CM_ "Nissan Leaf receive-side DBC for Cabana. Includes locally defined steering, blinkers, hazards, doors, pedals, wheel speed, gearbox, and related signals.";

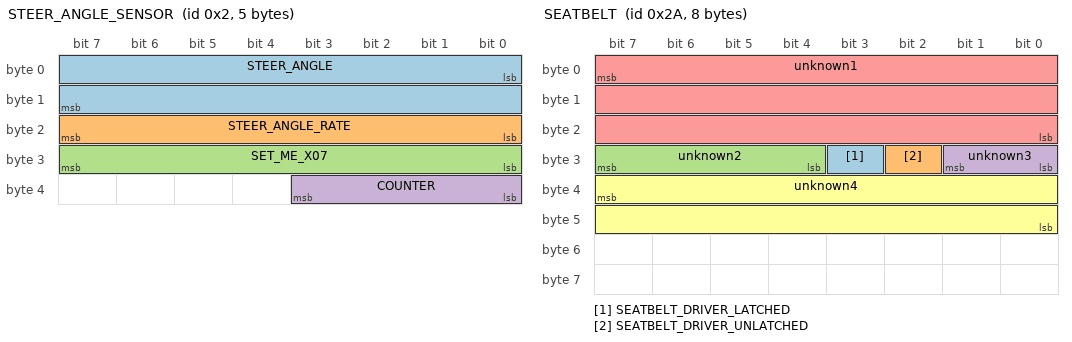
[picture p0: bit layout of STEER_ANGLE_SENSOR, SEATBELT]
BO_ 2 STEER_ANGLE_SENSOR: 5 XXX
 SG_ STEER_ANGLE : 0|16@1- (-0.1,0) [-3276.7|3276.8] "deg" XXX
 SG_ STEER_ANGLE_RATE : 16|8@1+ (1,0) [0|255] "" XXX
 SG_ SET_ME_X07 : 24|8@1+ (1,0) [0|255] "" XXX
 SG_ COUNTER : 32|4@1+ (1,0) [0|15] "" XXX

BO_ 42 SEATBELT: 8 XXX
 SG_ SEATBELT_DRIVER_LATCHED : 27|1@1+ (1,0) [0|3] "" XXX
 SG_ SEATBELT_DRIVER_UNLATCHED : 26|1@0+ (1,0) [0|1] "" XXX
 SG_ unknown2 : 31|4@0+ (1,0) [0|15] "" XXX
 SG_ unknown3 : 24|2@1+ (1,0) [0|3] "" XXX
 SG_ unknown1 : 7|24@0+ (1,0) [0|16777215] "" XXX
 SG_ unknown4 : 39|16@0+ (1,0) [0|65535] "" XXX

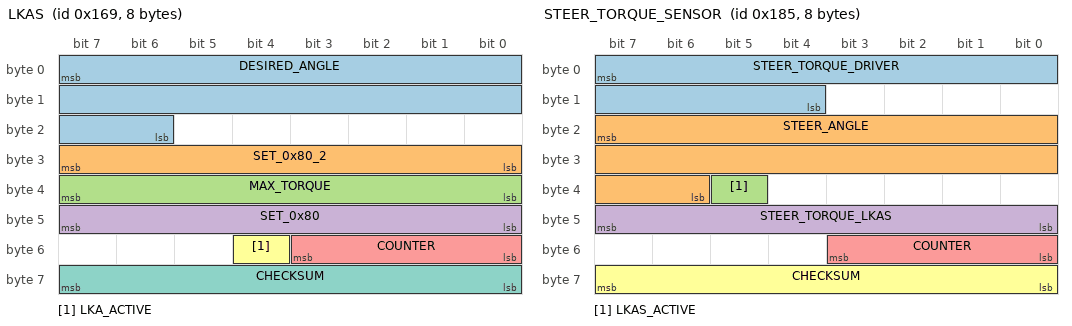
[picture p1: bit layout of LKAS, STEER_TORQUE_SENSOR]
BO_ 361 LKAS: 8 XXX
 SG_ DESIRED_ANGLE : 7|18@0+ (-0.01,1310) [-1311.43|1310] "deg" XXX
 SG_ SET_0x80_2 : 31|8@0+ (1,0) [0|255] "" XXX
 SG_ MAX_TORQUE : 39|8@0+ (0.01,0) [0|2.55] "Nm" XXX
 SG_ SET_0x80 : 47|8@0+ (1,0) [0|255] "" XXX
 SG_ COUNTER : 51|4@0+ (1,0) [0|15] "" XXX
 SG_ LKA_ACTIVE : 52|1@0+ (1,0) [0|1] "" XXX
 SG_ CHECKSUM : 63|8@0+ (1,0) [0|255] "" XXX

BO_ 389 STEER_TORQUE_SENSOR: 8 XXX
 SG_ STEER_TORQUE_DRIVER : 7|12@0+ (-0.01,20.47) [-20.48|20.47] "Nm" XXX
 SG_ STEER_ANGLE : 23|18@0+ (-0.01,1310) [-1311.43|1310] "deg" XXX
 SG_ LKAS_ACTIVE : 37|1@0+ (1,0) [0|1] "" XXX
 SG_ STEER_TORQUE_LKAS : 47|8@0+ (1,0) [0|255] "" XXX
 SG_ COUNTER : 51|4@0+ (1,0) [0|15] "" XXX
 SG_ CHECKSUM : 63|8@0+ (1,0) [0|255] "" XXX

BO_ 460 BRAKE_PEDAL: 8 XXX
 SG_ BRAKE_PEDAL : 7|8@0+ (1,0) [0|256] "" XXX

BO_ 569 CRUISE_THROTTLE: 8 XXX
 SG_ GAS_PEDAL_INVERTED : 15|8@0+ (1,0) [0|255] "" XXX
 SG_ GAS_PEDAL : 7|8@0+ (1,0) [0|255] "" XXX
 SG_ CRUISE_AVAILABLE : 17|1@0+ (1,0) [0|1] "" XXX
 SG_ unsure1 : 23|6@0+ (1,0) [0|63] "" XXX
 SG_ unsure2 : 16|1@0+ (1,0) [0|1] "" XXX
 SG_ unsure3 : 31|2@0+ (1,0) [0|3] "" XXX
 SG_ NO_BUTTON_PRESSED : 29|1@0+ (1,0) [0|1] "" XXX
 SG_ RES_BUTTON : 28|1@0+ (1,0) [0|1] "" XXX
 SG_ SET_BUTTON : 27|1@0+ (1,0) [0|1] "" XXX
 SG_ FOLLOW_DISTANCE_BUTTON : 26|1@0+ (1,0) [0|1] "" XXX
 SG_ CANCEL_BUTTON : 25|1@0+ (1,0) [0|1] "" XXX
 SG_ PROPILOT_BUTTON : 24|1@0+ (1,0) [0|1] "" XXX
 SG_ USER_BRAKE_PRESSED : 37|1@0+ (1,0) [0|1] "" XXX
 SG_ COUNTER : 32|2@1+ (1,0) [0|3] "" XXX
 SG_ unsure5 : 47|8@0+ (1,0) [0|255] "" XXX
 SG_ unsure6 : 55|8@0+ (1,0) [0|255] "" XXX
 SG_ unsure7 : 63|8@0+ (1,0) [0|255] "" XXX

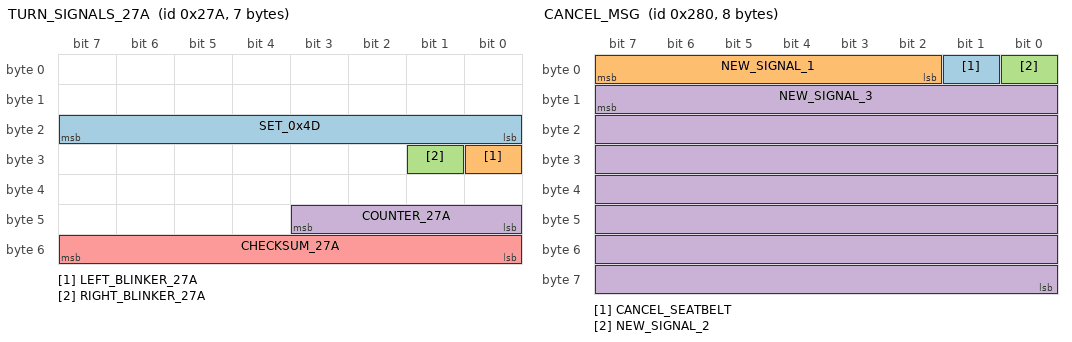
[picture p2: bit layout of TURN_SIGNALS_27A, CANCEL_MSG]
BO_ 634 TURN_SIGNALS_27A: 7 XXX
 SG_ SET_0x4D : 23|8@0+ (1,0) [0|255] "" XXX
 SG_ LEFT_BLINKER_27A : 24|1@0+ (1,0) [0|1] "" XXX
 SG_ RIGHT_BLINKER_27A : 25|1@0+ (1,0) [0|1] "" XXX
 SG_ COUNTER_27A : 43|4@0+ (1,0) [0|15] "" XXX
 SG_ CHECKSUM_27A : 55|8@0+ (1,0) [0|255] "" XXX

BO_ 640 CANCEL_MSG: 8 XXX
 SG_ CANCEL_SEATBELT : 1|1@0+ (1,0) [0|1] "" XXX
 SG_ NEW_SIGNAL_1 : 7|6@0+ (1,0) [0|63] "" XXX
 SG_ NEW_SIGNAL_2 : 0|1@0+ (1,0) [0|1] "" XXX
 SG_ NEW_SIGNAL_3 : 15|56@0+ (1,0) [0|72057594037927940] "" XXX

BO_ 644 WHEEL_SPEEDS_FRONT: 8 XXX
 SG_ WHEEL_SPEED_FR : 7|16@0+ (0.005,0) [0|65535] "KPH" XXX
 SG_ WHEEL_SPEED_FL : 23|16@0+ (0.005,0) [0|65535] "KPH" XXX

BO_ 852 ESP: 8 XXX
 SG_ ESP_DISABLED : 38|1@0+ (1,0) [0|1] "" XXX

BO_ 853 HUD_SETTINGS: 8 XXX
 SG_ SPEED_MPH : 37|1@0+ (1,0) [0|1] "" XXX

BO_ 856 LIGHTS: 8 XXX
 SG_ LEFT_BLINKER : 17|1@0+ (1,0) [0|1] "" XXX
 SG_ RIGHT_BLINKER : 18|1@0+ (1,0) [0|1] "" XXX

BO_ 943 HAZARD_SWITCH: 8 XXX
 SG_ HAZARD_BUTTON : 7|1@0+ (1,0) [0|1] "" XXX

BO_ 1057 GEARBOX: 3 XXX
 SG_ GEAR_SHIFTER : 5|3@0+ (1,0) [0|255] "" XXX

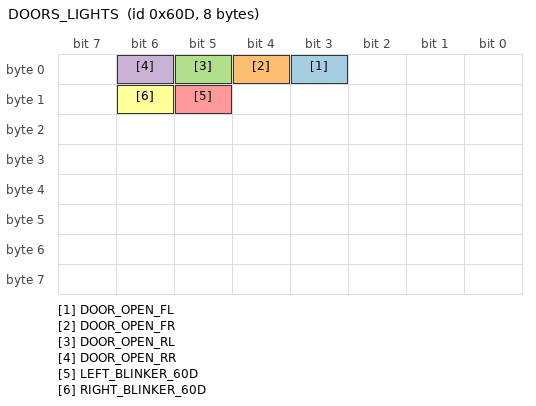
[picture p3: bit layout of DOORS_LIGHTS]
BO_ 1549 DOORS_LIGHTS: 8 XXX
 SG_ DOOR_OPEN_FL : 3|1@0+ (1,0) [0|1] "" XXX
 SG_ DOOR_OPEN_FR : 4|1@0+ (1,0) [0|1] "" XXX
 SG_ DOOR_OPEN_RL : 5|1@0+ (1,0) [0|1] "" XXX
 SG_ DOOR_OPEN_RR : 6|1@0+ (1,0) [0|1] "" XXX
 SG_ LEFT_BLINKER_60D : 13|1@0+ (1,0) [0|1] "" XXX
 SG_ RIGHT_BLINKER_60D : 14|1@0+ (1,0) [0|1] "" XXX

VAL_ 1057 GEAR_SHIFTER 7 "B" 4 "D" 3 "N" 2 "R" 1 "P" ;

CM_ BO_ 2 "Steering angle sensor. Our testing confirmed steering-angle behavior, steering-rate behavior, fixed 0x07 field, approximately 100 Hz transmission, and 4-bit rolling counter.";

CM_ SG_ 2 STEER_ANGLE "Tracks physical steering-wheel position. Known Nissan scaling is 0.1 degree/count.";

CM_ SG_ 2 STEER_ANGLE_RATE "Tracks steering movement rate. Slow movement produces smaller values, fast movement produces larger values, and held steering returns near zero.";

CM_ SG_ 2 COUNTER "Confirmed 4-bit rolling counter. Sequence 0 through 15 then wraps to 0.";

CM_ BO_ 361 "Known Nissan LKAS steering-control message. Our capture confirmed approximately 100 Hz transmission, fixed 0x80 fields, 4-bit rolling counter, and CRC-8/SAE-J1850 checksum. DESIRED_ANGLE, MAX_TORQUE, and LKA_ACTIVE are established Nissan definitions and were not independently proven by the stationary test.";

CM_ SG_ 361 COUNTER "Confirmed 4-bit rolling counter. Sequence 0 through 15 then wraps to 0.";

CM_ SG_ 361 CHECKSUM "Confirmed CRC-8/SAE-J1850 over data bytes 1 through 7. Polynomial 0x1D, initial value 0xFF, final XOR 0xFF. Checksum stored in byte 8.";

CM_ BO_ 389 "Steering torque sensor. Our testing supports separate driver-torque and steering-angle behavior. Exact Nm and degree scaling follows the established Nissan definition.";

CM_ SG_ 389 COUNTER "Confirmed 4-bit rolling counter. Sequence 0 through 15 then wraps to 0.";

CM_ SG_ 389 CHECKSUM "Confirmed CRC-8/SAE-J1850 over data bytes 1 through 7. Polynomial 0x1D, initial value 0xFF, final XOR 0xFF. Checksum stored in byte 8.";

CM_ BO_ 634 "Observed turn-signal state message. Byte 4 bit 0 = left, byte 4 bit 1 = right. Both active = hazard. Message observed at approximately 50 Hz and stops when vehicle is off. Captured on BUS 2 at 47.5 Hz over 50432 frames. REPORTS lamp state rather than commanding it: byte 4 toggles with the physical flash at about 1.43 Hz, and every sustained hazard period begins 20-30 ms AFTER a 0x3AF pulse. Transmitting this message is not expected to command the lamps.";

CM_ SG_ 634 SET_0x4D "Constant 0x4D across all 50432 captured frames. Was missing from this DBC, so frames we packed had 0x00 here and did not match what the car sends. Must be set on transmit.";

CM_ SG_ 634 COUNTER_27A "Confirmed 4-bit rolling counter in byte 6 low nibble. Sequence 0 through 15 then wraps to 0.";

CM_ SG_ 634 CHECKSUM_27A "Confirmed additive checksum. Checksum = (Byte1 + Byte2 + Byte3 + Byte4 + Byte5 + Byte6 + 0x7C) & 0xFF.";

CM_ BO_ 943 "Observed hazard-switch press message. Byte 1 bit 7 pulses when the physical hazard button is pressed. Same pulse occurs for hazard ON and hazard OFF. Captured on BUS 0 at 10.1 Hz; bytes 2-8 constant 0x00, no counter and no checksum. 110 pulses observed, width 0.131 s min / 0.250 s median / 0.560 s max, so a press is roughly 2-3 frames at 10 Hz. This is the COMMAND side of the hazard function: all 35 sustained hazard periods in 0x27A began 20-30 ms after a pulse here.";

CM_ BO_ 1549 "Door-status message also contains turn-signal state. Byte 2 bit 5 = left, byte 2 bit 6 = right. Both active = hazard. No obvious rolling counter or checksum observed. Captured on BUS 0 at 10.3 Hz. Byte 2 toggles 0x06 <-> 0x66 in lockstep with the 0x27A flash, which confirms bits 5 and 6 as the two blinker lamps (0x20 | 0x40 = 0x60). Byte 1 went 0x98 -> 0x90 -> 0x80 early in the capture, consistent with the two front doors being closed one after the other, which supports the DOOR_OPEN_FL/FR bit assignments. Like 0x27A this message REPORTS lamp state.";
